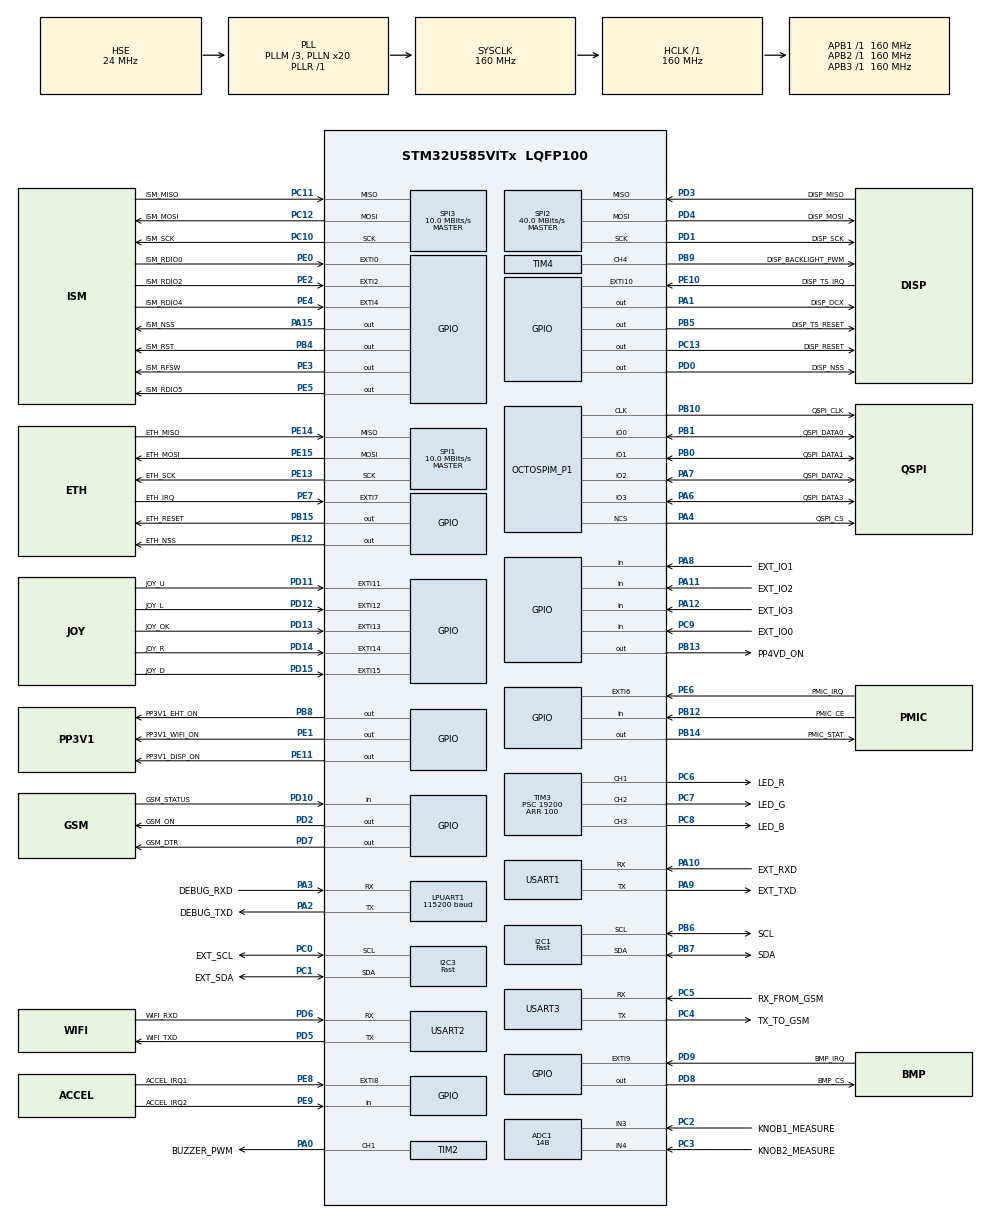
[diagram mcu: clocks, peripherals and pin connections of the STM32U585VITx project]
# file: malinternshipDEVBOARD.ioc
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ADC1.Channel-0\#ChannelRegularConversion=ADC_CHANNEL_3
ADC1.Channel-1\#ChannelRegularConversion=ADC_CHANNEL_4
ADC1.ClockPrescaler=ADC_CLOCK_ASYNC_DIV8
ADC1.ContinuousConvMode=ENABLE
ADC1.ConversionDataManagement=ADC_CONVERSIONDATA_DMA_CIRCULAR
ADC1.EOCSelection=ADC_EOC_SEQ_CONV
ADC1.EnableInjectedConversion=DISABLE
ADC1.EnableRegularConversion=ENABLE
ADC1.MonitoredBy-0\#ChannelRegularConversion=__NULL
ADC1.MonitoredBy-1\#ChannelRegularConversion=__NULL
ADC1.NbrOfConversion=2
ADC1.NbrOfConversionFlag=1
ADC1.OffsetNumber-0\#ChannelRegularConversion=ADC_OFFSET_NONE
ADC1.OffsetNumber-1\#ChannelRegularConversion=ADC_OFFSET_NONE
ADC1.OversamplingMode=ENABLE
ADC1.Rank-0\#ChannelRegularConversion=1
ADC1.Rank-1\#ChannelRegularConversion=2
ADC1.Ratio=15
ADC1.Resolution=ADC_RESOLUTION_14B
ADC1.SamplingTime-0\#ChannelRegularConversion=ADC_SAMPLETIME_68CYCLES
ADC1.SamplingTime-1\#ChannelRegularConversion=ADC_SAMPLETIME_68CYCLES
ADC1.TriggerFrequencyMode=ADC_TRIGGER_FREQ_HIGH
ADC1.master=1
CORTEX_M33_NS.userName=CORTEX_M33
GPDMA1.CIRCULARMODE_GPDMACH0=DISABLE
GPDMA1.CIRCULARMODE_GPDMACH5=ENABLE
GPDMA1.CIRCULARMODE_GPDMACH9=ENABLE
GPDMA1.DATAHANDLING_GPDMACH5=NONE
GPDMA1.DESTDATAWIDTH_GPDMACH5=DMA_DEST_DATAWIDTH_WORD
GPDMA1.DESTINC_GPDMACH0=DMA_DINC_FIXED
GPDMA1.DESTINC_GPDMACH2=DMA_DINC_INCREMENTED
GPDMA1.DESTINC_GPDMACH4=DMA_DINC_INCREMENTED
GPDMA1.DESTINC_GPDMACH5=DMA_DINC_INCREMENTED
GPDMA1.DESTINC_GPDMACH6=DMA_DINC_INCREMENTED
GPDMA1.DESTINC_GPDMACH9=DMA_DINC_INCREMENTED
GPDMA1.DIRECTION_GPDMACH0=DMA_MEMORY_TO_PERIPH
GPDMA1.DIRECTION_GPDMACH1=DMA_MEMORY_TO_PERIPH
GPDMA1.DIRECTION_GPDMACH3=DMA_MEMORY_TO_PERIPH
GPDMA1.DIRECTION_GPDMACH7=DMA_MEMORY_TO_PERIPH
GPDMA1.IPHANDLE_GPDMACH0-SIMPLEREQUEST_GPDMACH0=__NULL
GPDMA1.IPHANDLE_GPDMACH1-SIMPLEREQUEST_GPDMACH1=__NULL
GPDMA1.IPHANDLE_GPDMACH2-SIMPLEREQUEST_GPDMACH2=__NULL
GPDMA1.IPHANDLE_GPDMACH3-SIMPLEREQUEST_GPDMACH3=__NULL
GPDMA1.IPHANDLE_GPDMACH4-SIMPLEREQUEST_GPDMACH4=__NULL
GPDMA1.IPHANDLE_GPDMACH5-SIMPLEREQUEST_GPDMACH5=__NULL
GPDMA1.IPHANDLE_GPDMACH6-SIMPLEREQUEST_GPDMACH6=__NULL
GPDMA1.IPHANDLE_GPDMACH7-SIMPLEREQUEST_GPDMACH7=__NULL
GPDMA1.IPHANDLE_GPDMACH8-SIMPLEREQUEST_GPDMACH8=__NULL
GPDMA1.IPHANDLE_GPDMACH9-SIMPLEREQUEST_GPDMACH9=__NULL
GPDMA1.PRIORITY_GPDMACH0=DMA_LOW_PRIORITY_MID_WEIGHT
GPDMA1.PRIORITY_GPDMACH1=DMA_LOW_PRIORITY_MID_WEIGHT
GPDMA1.PRIORITY_GPDMACH2=DMA_LOW_PRIORITY_HIGH_WEIGHT
GPDMA1.PRIORITY_GPDMACH3=DMA_LOW_PRIORITY_MID_WEIGHT
GPDMA1.PRIORITY_GPDMACH4=DMA_LOW_PRIORITY_HIGH_WEIGHT
GPDMA1.PRIORITY_GPDMACH8=DMA_LOW_PRIORITY_HIGH_WEIGHT
GPDMA1.PRIORITY_LL_CIRCULAR_GPDMACH5=DMA_LOW_PRIORITY_MID_WEIGHT
GPDMA1.PRIORITY_LL_CIRCULAR_GPDMACH9=DMA_LOW_PRIORITY_HIGH_WEIGHT
GPDMA1.REQUEST_GPDMACH0=GPDMA1_REQUEST_LPUART1_TX
GPDMA1.REQUEST_GPDMACH1=GPDMA1_REQUEST_I2C1_TX
GPDMA1.REQUEST_GPDMACH2=GPDMA1_REQUEST_I2C1_RX
GPDMA1.REQUEST_GPDMACH3=GPDMA1_REQUEST_I2C3_TX
GPDMA1.REQUEST_GPDMACH4=GPDMA1_REQUEST_I2C3_RX
GPDMA1.REQUEST_GPDMACH5=GPDMA1_REQUEST_ADC1
GPDMA1.REQUEST_GPDMACH6=GPDMA1_REQUEST_SPI3_RX
GPDMA1.REQUEST_GPDMACH7=GPDMA1_REQUEST_SPI3_TX
GPDMA1.REQUEST_GPDMACH8=GPDMA1_REQUEST_SPI2_TX
GPDMA1.REQUEST_GPDMACH9=GPDMA1_REQUEST_USART1_RX
GPDMA1.SRCDATAWIDTH_GPDMACH5=DMA_SRC_DATAWIDTH_WORD
GPDMA1.SRCINC_GPDMACH0=DMA_SINC_INCREMENTED
GPDMA1.SRCINC_GPDMACH1=DMA_SINC_INCREMENTED
GPDMA1.SRCINC_GPDMACH3=DMA_SINC_INCREMENTED
GPDMA1.SRCINC_GPDMACH7=DMA_SINC_INCREMENTED
GPDMA1.SRCINC_GPDMACH8=DMA_SINC_INCREMENTED
I2C1.I2C_Speed_Mode=I2C_Fast
I2C1.Timing=0x00F07BFF
I2C3.I2C_Speed_Mode=I2C_Fast
I2C3.Timing=0x00F07BFF
IWDG.Prescaler=IWDG_PRESCALER_16
LPUART1.BaudRate=115200
Mcu.Family=STM32U5
Mcu.Name=STM32U585VITx
Mcu.Package=LQFP100
Mcu.UserConstants=I2C,hi2c1;EXT_I2C,hi2c3;LOG_UART,hlpuart1;FLASH_QSPI,hospi1;ETH_SPI,hspi1;DISP_SPI,hspi2;RFM_SPI,hspi3;EXT_UART,huart1;WIFI_UART,huart2;MODEM_UART,huart3;LED_R_TIM,htim3;LED_R_CH,TIM_CHANNEL_1;LED_G_TIM,htim3;LED_G_CH,TIM_CHANNEL_2;LED_B_TIM,htim3;LED_B_CH,TIM_CHANNEL_3
NVIC.ADC1_IRQn=true\:0\:0\:false\:false\:true\:false\:true\:true\:true
NVIC.EXTI0_IRQn=true\:0\:0\:false\:false\:true\:false\:true\:true\:true
NVIC.EXTI10_IRQn=true\:0\:0\:false\:false\:true\:false\:true\:true\:true
NVIC.EXTI11_IRQn=true\:0\:0\:false\:false\:true\:false\:true\:true\:true
NVIC.EXTI12_IRQn=true\:0\:0\:false\:false\:true\:false\:true\:true\:true
NVIC.EXTI13_IRQn=true\:0\:0\:false\:false\:true\:false\:true\:true\:true
NVIC.EXTI14_IRQn=true\:0\:0\:false\:false\:true\:false\:true\:true\:true
NVIC.EXTI15_IRQn=true\:0\:0\:false\:false\:true\:false\:true\:true\:true
NVIC.EXTI2_IRQn=true\:0\:0\:false\:false\:true\:false\:true\:true\:true
NVIC.EXTI4_IRQn=true\:0\:0\:false\:false\:true\:false\:true\:true\:true
NVIC.EXTI6_IRQn=true\:0\:0\:false\:false\:true\:false\:true\:true\:true
NVIC.EXTI7_IRQn=true\:0\:0\:false\:false\:true\:false\:true\:true\:true
NVIC.EXTI8_IRQn=true\:0\:0\:false\:false\:true\:false\:true\:true\:true
NVIC.EXTI9_IRQn=true\:0\:0\:false\:false\:true\:false\:true\:true\:true
NVIC.GPDMA1_Channel0_IRQn=true\:0\:0\:false\:false\:true\:true\:false\:true\:true
NVIC.GPDMA1_Channel1_IRQn=true\:0\:0\:false\:false\:true\:true\:false\:true\:true
NVIC.GPDMA1_Channel2_IRQn=true\:0\:0\:false\:false\:true\:true\:false\:true\:true
NVIC.GPDMA1_Channel3_IRQn=true\:0\:0\:false\:false\:true\:true\:false\:true\:true
NVIC.GPDMA1_Channel4_IRQn=true\:0\:0\:false\:false\:true\:true\:false\:true\:true
NVIC.GPDMA1_Channel5_IRQn=true\:0\:0\:false\:false\:true\:true\:false\:true\:true
NVIC.GPDMA1_Channel6_IRQn=true\:0\:0\:false\:false\:true\:true\:false\:true\:true
NVIC.GPDMA1_Channel7_IRQn=true\:0\:0\:false\:false\:true\:true\:false\:true\:true
NVIC.GPDMA1_Channel8_IRQn=true\:0\:0\:false\:false\:true\:true\:false\:true\:true
NVIC.GPDMA1_Channel9_IRQn=true\:0\:0\:false\:false\:true\:true\:false\:true\:true
NVIC.I2C1_ER_IRQn=true\:5\:0\:true\:false\:true\:false\:true\:true\:true
NVIC.I2C1_EV_IRQn=true\:5\:0\:true\:false\:true\:false\:true\:true\:true
NVIC.I2C3_ER_IRQn=true\:5\:0\:true\:false\:true\:false\:true\:true\:true
NVIC.I2C3_EV_IRQn=true\:5\:0\:true\:false\:true\:false\:true\:true\:true
NVIC.IWDG_IRQn=true\:0\:0\:false\:false\:true\:false\:true\:true\:true
NVIC.LPUART1_IRQn=true\:0\:0\:false\:false\:true\:false\:true\:true\:true
NVIC.OCTOSPI1_IRQn=true\:0\:0\:false\:false\:true\:false\:true\:true\:true
NVIC.PriorityGroup=NVIC_PRIORITYGROUP_4
NVIC.SPI2_IRQn=true\:0\:0\:false\:false\:true\:false\:true\:true\:true
NVIC.SPI3_IRQn=true\:0\:0\:false\:false\:true\:false\:false\:true\:true
NVIC.TIM17_IRQn=true\:15\:0\:false\:false\:true\:false\:false\:true\:true
NVIC.TIM2_IRQn=true\:4\:0\:true\:false\:true\:false\:true\:true\:true
NVIC.TIM7_IRQn=true\:0\:0\:false\:false\:true\:false\:true\:true\:true
NVIC.TimeBase=TIM17_IRQn
NVIC.TimeBaseIP=TIM17
NVIC.USART1_IRQn=true\:0\:0\:false\:false\:true\:false\:true\:true\:true
OCTOSPI1.ClockPrescaler=6
OCTOSPI1.DeviceSize=24
PA0.GPIO_Label=BUZZER_PWM
PA0.PinAttribute=Free
PA0.Signal=S_TIM2_CH1
PA1.GPIO_Label=DISP_DCX
PA1.PinAttribute=Free
PA1.Signal=GPIO_Output
PA10.GPIO_Label=EXT_RXD
PA10.GPIO_PuPd=GPIO_PULLUP
PA10.Mode=Asynchronous
PA10.PinAttribute=Free
PA10.Signal=USART1_RX
PA11.GPIO_Label=EXT_IO2
PA11.GPIO_PuPd=GPIO_PULLUP
PA11.PinAttribute=Free
PA11.Signal=GPIO_Input
PA12.GPIO_Label=EXT_IO3
PA12.GPIO_PuPd=GPIO_PULLUP
PA12.PinAttribute=Free
PA12.Signal=GPIO_Input
PA13\ (JTMS/SWDIO).Mode=Serial_Wire
PA13\ (JTMS/SWDIO).PinAttribute=Free
PA13\ (JTMS/SWDIO).Signal=DEBUG_JTMS-SWDIO
PA14\ (JTCK/SWCLK).Mode=Serial_Wire
PA14\ (JTCK/SWCLK).PinAttribute=Free
PA14\ (JTCK/SWCLK).Signal=DEBUG_JTCK-SWCLK
PA15\ (JTDI).GPIO_Label=ISM_NSS
PA15\ (JTDI).GPIO_Speed=GPIO_SPEED_FREQ_LOW
PA15\ (JTDI).PinState=GPIO_PIN_SET
PA15\ (JTDI).Signal=GPIO_Output
PA2.GPIO_Label=DEBUG_TXD
PA2.Mode=Asynchronous
PA2.PinAttribute=Free
PA2.Signal=LPUART1_TX
PA3.GPIO_Label=DEBUG_RXD
PA3.Mode=Asynchronous
PA3.PinAttribute=Free
PA3.Signal=LPUART1_RX
PA4.GPIO_Label=QSPI_CS
PA4.Mode=OCTOSPI1_Port1_NCS
PA4.Signal=OCTOSPIM_P1_NCS
PA6.GPIO_Label=QSPI_DATA3
PA6.Mode=OCTOSPI1_IOL_Port1L
PA6.Signal=OCTOSPIM_P1_IO3
PA7.GPIO_Label=QSPI_DATA2
PA7.Mode=OCTOSPI1_IOL_Port1L
PA7.Signal=OCTOSPIM_P1_IO2
PA8.GPIO_Label=EXT_IO1
PA8.GPIO_PuPd=GPIO_PULLUP
PA8.PinAttribute=Free
PA8.Signal=GPIO_Input
PA9.GPIO_Label=EXT_TXD
PA9.GPIO_PuPd=GPIO_PULLUP
PA9.Mode=Asynchronous
PA9.PinAttribute=Free
PA9.Signal=USART1_TX
PB0.GPIO_Label=QSPI_DATA1
PB0.Mode=OCTOSPI1_IOL_Port1L
PB0.Signal=OCTOSPIM_P1_IO1
PB1.GPIO_Label=QSPI_DATA0
PB1.Mode=OCTOSPI1_IOL_Port1L
PB1.Signal=OCTOSPIM_P1_IO0
PB10.GPIO_Label=QSPI_CLK
PB10.Mode=O1_P1_CLK
PB10.Signal=OCTOSPIM_P1_CLK
PB12.GPIO_Label=PMIC_CE
PB12.Signal=GPIO_Input
PB13.GPIO_Label=PP4VD_ON
PB13.Signal=GPIO_Output
PB14.GPIO_Label=PMIC_STAT
PB14.Signal=GPIO_Output
PB15.GPIO_Label=ETH_RESET
PB15.Signal=GPIO_Output
PB2.GPIO_Label=EXT_SMBA
PB2.Signal=I2C3_SMBA
PB4\ (NJTRST).GPIO_Label=ISM_RST
PB4\ (NJTRST).Signal=GPIO_Output
PB5.GPIO_Label=DISP_TS_RESET
PB5.Signal=GPIO_Output
PB6.GPIO_Label=SCL
PB6.GPIO_Speed=GPIO_SPEED_FREQ_HIGH
PB6.Mode=I2C
PB6.Signal=I2C1_SCL
PB7.GPIO_Label=SDA
PB7.GPIO_Speed=GPIO_SPEED_FREQ_HIGH
PB7.Mode=I2C
PB7.Signal=I2C1_SDA
PB8.GPIO_Label=PP3V1_EHT_ON
PB8.Signal=GPIO_Output
PB9.GPIO_Label=DISP_BACKLIGHT_PWM
PB9.Signal=S_TIM4_CH4
PC0.GPIO_Label=EXT_SCL
PC0.GPIO_Speed=GPIO_SPEED_FREQ_HIGH
PC0.Mode=I2C
PC0.PinAttribute=Free
PC0.Signal=I2C3_SCL
PC1.GPIO_Label=EXT_SDA
PC1.GPIO_Speed=GPIO_SPEED_FREQ_HIGH
PC1.Mode=I2C
PC1.PinAttribute=Free
PC1.Signal=I2C3_SDA
PC10.GPIO_Label=ISM_SCK
PC10.Mode=Full_Duplex_Master
PC10.Signal=SPI3_SCK
PC11.GPIO_Label=ISM_MISO
PC11.Mode=Full_Duplex_Master
PC11.Signal=SPI3_MISO
PC12.GPIO_Label=ISM_MOSI
PC12.Mode=Full_Duplex_Master
PC12.PinAttribute=Free
PC12.Signal=SPI3_MOSI
PC13.GPIO_Label=DISP_RESET
PC13.Signal=GPIO_Output
PC14-OSC32_IN\ (PC14).Mode=LSE-External-Oscillator
PC14-OSC32_IN\ (PC14).Signal=RCC_OSC32_IN
PC15-OSC32_OUT\ (PC15).Mode=LSE-External-Oscillator
PC15-OSC32_OUT\ (PC15).Signal=RCC_OSC32_OUT
PC2.GPIO_Label=KNOB1_MEASURE
PC2.Mode=IN3-Single-Ended
PC2.PinAttribute=Free
PC2.Signal=ADC1_IN3
PC3.GPIO_Label=KNOB2_MEASURE
PC3.Mode=IN4-Single-Ended
PC3.PinAttribute=Free
PC3.Signal=ADC1_IN4
PC4.GPIO_Label=TX_TO_GSM
PC4.Mode=Asynchronous
PC4.Signal=USART3_TX
PC5.GPIO_Label=RX_FROM_GSM
PC5.Mode=Asynchronous
PC5.Signal=USART3_RX
PC6.GPIO_Label=LED_R
PC6.Signal=S_TIM3_CH1
PC7.GPIO_Label=LED_G
PC7.Signal=S_TIM3_CH2
PC8.GPIO_Label=LED_B
PC8.PinAttribute=Free
PC8.Signal=S_TIM3_CH3
PC9.GPIO_Label=EXT_IO0
PC9.GPIO_PuPd=GPIO_PULLUP
PC9.PinAttribute=Free
PC9.Signal=GPIO_Input
PD0.GPIO_Label=DISP_NSS
PD0.GPIO_Speed=GPIO_SPEED_FREQ_LOW
PD0.PinAttribute=Free
PD0.PinState=GPIO_PIN_SET
PD0.Signal=GPIO_Output
PD1.GPIO_Label=DISP_SCK
PD1.GPIO_Speed=GPIO_SPEED_FREQ_VERY_HIGH
PD1.Mode=Full_Duplex_Master
PD1.PinAttribute=Free
PD1.Signal=SPI2_SCK
PD10.GPIO_Label=GSM_STATUS
PD10.Signal=GPIO_Input
PD11.GPIO_Label=JOY_U
PD11.GPIO_ModeDefaultEXTI=GPIO_MODE_IT_RISING_FALLING
PD11.Signal=GPXTI11
PD12.GPIO_Label=JOY_L
PD12.GPIO_ModeDefaultEXTI=GPIO_MODE_IT_RISING_FALLING
PD12.PinAttribute=Free
PD12.Signal=GPXTI12
PD13.GPIO_Label=JOY_OK
PD13.GPIO_ModeDefaultEXTI=GPIO_MODE_IT_RISING_FALLING
PD13.PinAttribute=Free
PD13.Signal=GPXTI13
PD14.GPIO_Label=JOY_R
PD14.GPIO_ModeDefaultEXTI=GPIO_MODE_IT_RISING_FALLING
PD14.Signal=GPXTI14
PD15.GPIO_Label=JOY_D
PD15.GPIO_ModeDefaultEXTI=GPIO_MODE_IT_RISING_FALLING
PD15.GPIO_PuPd=GPIO_NOPULL
PD15.Signal=GPXTI15
PD2.GPIO_Label=GSM_ON
PD2.PinAttribute=Free
PD2.Signal=GPIO_Output
PD3.GPIO_Label=DISP_MISO
PD3.GPIO_Speed=GPIO_SPEED_FREQ_VERY_HIGH
PD3.Mode=Full_Duplex_Master
PD3.Signal=SPI2_MISO
PD4.GPIO_Label=DISP_MOSI
PD4.GPIO_Speed=GPIO_SPEED_FREQ_VERY_HIGH
PD4.Mode=Full_Duplex_Master
PD4.Signal=SPI2_MOSI
PD5.GPIO_Label=WIFI_TXD
PD5.Mode=Asynchronous
PD5.Signal=USART2_TX
PD6.GPIO_Label=WIFI_RXD
PD6.Mode=Asynchronous
PD6.Signal=USART2_RX
PD7.GPIO_Label=GSM_DTR
PD7.Signal=GPIO_Output
PD8.GPIO_Label=BMP_CS
PD8.GPIO_Speed=GPIO_SPEED_FREQ_LOW
PD8.PinState=GPIO_PIN_SET
PD8.Signal=GPIO_Output
PD9.GPIO_Label=BMP_IRQ
PD9.Signal=GPXTI9
PE0.GPIO_Label=ISM_RDIO0
PE0.GPIO_ModeDefaultEXTI=GPIO_MODE_IT_FALLING
PE0.Signal=GPXTI0
PE1.GPIO_Label=PP3V1_WIFI_ON
PE1.Signal=GPIO_Output
PE10.GPIO_Label=DISP_TS_IRQ
PE10.Signal=GPXTI10
PE11.GPIO_Label=PP3V1_DISP_ON
PE11.Signal=GPIO_Output
PE12.GPIO_Label=ETH_NSS
PE12.GPIO_Speed=GPIO_SPEED_FREQ_LOW
PE12.PinState=GPIO_PIN_SET
PE12.Signal=GPIO_Output
PE13.GPIO_Label=ETH_SCK
PE13.Mode=Full_Duplex_Master
PE13.Signal=SPI1_SCK
PE14.GPIO_Label=ETH_MISO
PE14.Mode=Full_Duplex_Master
PE14.Signal=SPI1_MISO
PE15.GPIO_Label=ETH_MOSI
PE15.Mode=Full_Duplex_Master
PE15.Signal=SPI1_MOSI
PE2.GPIO_Label=ISM_RDIO2
PE2.GPIO_ModeDefaultEXTI=GPIO_MODE_IT_RISING
PE2.Signal=GPXTI2
PE3.GPIO_Label=ISM_RFSW
PE3.Signal=GPIO_Output
PE4.GPIO_Label=ISM_RDIO4
PE4.GPIO_ModeDefaultEXTI=GPIO_MODE_IT_RISING_FALLING
PE4.Signal=GPXTI4
PE5.GPIO_Label=ISM_RDIO5
PE5.Signal=GPIO_Output
PE6.GPIO_Label=PMIC_IRQ
PE6.Signal=GPXTI6
PE7.GPIO_Label=ETH_IRQ
PE7.Signal=GPXTI7
PE8.GPIO_Label=ACCEL_IRQ1
PE8.Signal=GPXTI8
PE9.GPIO_Label=ACCEL_IRQ2
PE9.Signal=GPIO_Input
PH0-OSC_IN\ (PH0).Mode=HSE-External-Oscillator
PH0-OSC_IN\ (PH0).Signal=RCC_OSC_IN
PH1-OSC_OUT\ (PH1).Mode=HSE-External-Oscillator
PH1-OSC_OUT\ (PH1).Signal=RCC_OSC_OUT
ProjectManager.HeapSize=0x200
ProjectManager.StackSize=0x400
ProjectManager.TargetToolchain=Makefile
RCC.ADCFreq_Value=16000000
RCC.AHBFreq_Value=160000000
RCC.APB1Freq_Value=160000000
RCC.APB1TimFreq_Value=160000000
RCC.APB2Freq_Value=160000000
RCC.APB2TimFreq_Value=160000000
RCC.APB3Freq_Value=160000000
RCC.CortexFreq_Value=160000000
RCC.DACCLockSelectionVirtual=RCC_DAC1CLKSOURCE_LSI
RCC.DACCLockSelectionVirtualString=RCC_DAC1CLKSOURCE_LSI
RCC.EPOD_VALUE=24000000
RCC.HCLKFreq_Value=160000000
RCC.HSE_VALUE=24000000
RCC.HSI48_VALUE=48000000
RCC.HSI_VALUE=16000000
RCC.LSIDIV_VALUE=32000
RCC.MSIClockRange=RCC_MSIRANGE_0
RCC.MSI_VALUE=48000000
RCC.PLL1R=1
RCC.PLL2FRACN=0
RCC.PLL3FRACN=0
RCC.PLLFRACN=0
RCC.PLLM=3
RCC.PLLN=20
RCC.PLLSourceVirtual=RCC_PLLSOURCE_HSE
RCC.SYSCLKFreq_VALUE=160000000
RCC.SYSCLKSource=RCC_SYSCLKSOURCE_PLLCLK
RCC.USBFreq_Value=48000000
RCC.VCOOutputFreq_Value=160000000
SH.S_TIM2_CH1.0=TIM2_CH1,PWM Generation1 CH1
SH.S_TIM3_CH1.0=TIM3_CH1,PWM Generation1 CH1
SH.S_TIM3_CH2.0=TIM3_CH2,PWM Generation2 CH2
SH.S_TIM3_CH3.0=TIM3_CH3,PWM Generation3 CH3
SH.S_TIM4_CH4.0=TIM4_CH4,PWM Generation4 CH4
SPI1.BaudRatePrescaler=SPI_BAUDRATEPRESCALER_16
SPI1.CalculateBaudRate=10.0 MBits/s
SPI1.DataSize=SPI_DATASIZE_8BIT
SPI1.Direction=SPI_DIRECTION_2LINES
SPI1.Mode=SPI_MODE_MASTER
SPI1.VirtualType=VM_MASTER
SPI2.BaudRatePrescaler=SPI_BAUDRATEPRESCALER_4
SPI2.CalculateBaudRate=40.0 MBits/s
SPI2.DataSize=SPI_DATASIZE_8BIT
SPI2.Direction=SPI_DIRECTION_2LINES
SPI2.Mode=SPI_MODE_MASTER
SPI2.VirtualType=VM_MASTER
SPI3.BaudRatePrescaler=SPI_BAUDRATEPRESCALER_16
SPI3.CalculateBaudRate=10.0 MBits/s
SPI3.Direction=SPI_DIRECTION_2LINES
SPI3.Mode=SPI_MODE_MASTER
SPI3.VirtualType=VM_MASTER
THREADX.TX_APP_MEM_POOL_SIZE=(64*1024)
THREADX.TX_MINIMUM_STACK=512
THREADX.TX_TIMER_THREAD_PRIORITY=2
THREADX.TX_TIMER_TICKS_PER_SECOND=1000
TIM2.Channel-PWM\ Generation1\ CH1=TIM_CHANNEL_1
TIM2.PeriodNoDither=256-1
TIM2.Prescaler=5-1
TIM3.AutoReloadPreload=TIM_AUTORELOAD_PRELOAD_ENABLE
TIM3.Channel-PWM\ Generation1\ CH1=TIM_CHANNEL_1
TIM3.Channel-PWM\ Generation2\ CH2=TIM_CHANNEL_2
TIM3.Channel-PWM\ Generation3\ CH3=TIM_CHANNEL_3
TIM3.PeriodNoDither=100
TIM3.Prescaler=19200
TIM4.AutoReloadPreload=TIM_AUTORELOAD_PRELOAD_ENABLE
TIM4.Channel-PWM\ Generation4\ CH4=TIM_CHANNEL_4
TIM4.PeriodNoDither=100
TIM4.Prescaler=5000
TIM7.PeriodNoDither=64000-1
TIM7.Prescaler=100-1
USART1.VirtualMode-Asynchronous=VM_ASYNC
USART2.VirtualMode-Asynchronous=VM_ASYNC
USART3.VirtualMode-Asynchronous=VM_ASYNC
VP_GPDMA1_VS_GPDMACH0.Mode=SIMPLEREQUEST_GPDMACH0
VP_GPDMA1_VS_GPDMACH1.Mode=SIMPLEREQUEST_GPDMACH1
VP_GPDMA1_VS_GPDMACH2.Mode=SIMPLEREQUEST_GPDMACH2
VP_GPDMA1_VS_GPDMACH3.Mode=SIMPLEREQUEST_GPDMACH3
VP_GPDMA1_VS_GPDMACH4.Mode=SIMPLEREQUEST_GPDMACH4
VP_GPDMA1_VS_GPDMACH5.Mode=SIMPLEREQUEST_GPDMACH5
VP_GPDMA1_VS_GPDMACH6.Mode=SIMPLEREQUEST_GPDMACH6
VP_GPDMA1_VS_GPDMACH7.Mode=SIMPLEREQUEST_GPDMACH7
VP_GPDMA1_VS_GPDMACH8.Mode=SIMPLEREQUEST_GPDMACH8
VP_GPDMA1_VS_GPDMACH9.Mode=SIMPLEREQUEST_GPDMACH9
VP_ICACHE_VS_ICACHE.Mode=DirectMappedCache
VP_IWDG_VS_IWDG.Mode=IWDG_Activate
VP_LPBAMQUEUE_VS_QUEUE.Mode=QUEUEMODE
VP_LPBAM_VS_SIG1.Mode=SmartRun
VP_LPBAM_VS_SIG4.Mode=LPDMA1
VP_OCTOSPI1_VS_quad.Mode=quad_mode
VP_PWR_VS_DBSignals.Mode=DisableDeadBatterySignals
VP_PWR_VS_LPOM.Mode=PowerOptimisation
VP_PWR_VS_SECSignals.Mode=Security/Privilege
VP_SYS_VS_tim17.Mode=TIM17
VP_THREADX_VS_RTOSJjThreadXJjCoreJjDefault.Mode=Core_Default
VP_TIM2_VS_ClockSourceINT.Mode=Internal
VP_TIM3_VS_ClockSourceINT.Mode=Internal
VP_TIM4_VS_ClockSourceINT.Mode=Internal
VP_TIM7_VS_ClockSourceINT.Mode=Enable_Timer
board=custom

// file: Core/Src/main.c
/* USER CODE BEGIN Header */
/**
 ******************************************************************************
 * @file           : main.c
 * @brief          : Main program body
 ******************************************************************************
 * @attention
 *
 * Copyright (c) 2022 STMicroelectronics.
 * All rights reserved.
 *
 * This software is licensed under terms that can be found in the LICENSE file
 * in the root directory of this software component.
 * If no LICENSE file comes with this software, it is provided AS-IS.
 *
 ******************************************************************************
 */
/* USER CODE END Header */
#include "main.h"
#include "app_threadx.h"
#include "adc.h"
#include "gpdma.h"
#include "i2c.h"
#include "icache.h"
#include "iwdg.h"
#include "usart.h"
#include "octospi.h"
#include "spi.h"
#include "tim.h"
#include "gpio.h"

/* USER CODE BEGIN Includes */
#include "loglib.h"
#include "esp32.h"
#include "parser.h"
#include "buzzer.h"
#include "boot_reason.h"
#include "display.h"
#include "flash.h"
#include "rfm66a.h"
#include "geode.h"

/* USER CODE END Includes */

void        SystemClock_Config(void);
static void SystemPower_Config(void);

int main(void) {

    /* MCU Configuration--------------------------------------------------------*/

    /* Reset of all peripherals, Initializes the Flash interface and the Systick. */
    HAL_Init();

    /* Configure the system clock */
    SystemClock_Config();

    /* Configure the System Power */
    SystemPower_Config();

    /* USER CODE BEGIN SysInit */
    GENERAL_GetResetStatus();

    HAL_PWREx_EnableVddA();
    /* USER CODE END SysInit */

    /* Initialize all configured peripherals */
    MX_GPIO_Init();
    MX_GPDMA1_Init();
    MX_SPI2_Init();
    MX_TIM4_Init();
    MX_I2C1_Init();
    MX_I2C3_Init();
    MX_USART1_UART_Init();
    MX_SPI3_Init();
    MX_SPI1_Init();
    MX_USART2_UART_Init();
    MX_ADC1_Init();
    MX_LPUART1_UART_Init();
    MX_USART3_UART_Init();
    MX_TIM3_Init();
    MX_OCTOSPI1_Init();
    MX_TIM2_Init();
    MX_ICACHE_Init();
    MX_IWDG_Init();
    MX_TIM7_Init();

    MX_ThreadX_Init();

    /* We should never get here as control is now taken by the scheduler */
    /* Infinite loop */
    while (1) {

    }
}

void SystemClock_Config(void) {
    RCC_OscInitTypeDef RCC_OscInitStruct = { 0 };
    RCC_ClkInitTypeDef RCC_ClkInitStruct = { 0 };

    /** Configure the main internal regulator output voltage
     */
    if (HAL_PWREx_ControlVoltageScaling(PWR_REGULATOR_VOLTAGE_SCALE1) != HAL_OK) {
        Error_Handler();
    }

    /** Initializes the CPU, AHB and APB buses clocks
     */
    RCC_OscInitStruct.OscillatorType = RCC_OSCILLATORTYPE_HSI | RCC_OSCILLATORTYPE_LSI | RCC_OSCILLATORTYPE_HSE;
    RCC_OscInitStruct.HSEState = RCC_HSE_ON;
    RCC_OscInitStruct.HSIState = RCC_HSI_ON;
    RCC_OscInitStruct.HSICalibrationValue = RCC_HSICALIBRATION_DEFAULT;
    RCC_OscInitStruct.LSIState = RCC_LSI_ON;
    RCC_OscInitStruct.LSIDiv = RCC_LSI_DIV1;
    RCC_OscInitStruct.PLL.PLLState = RCC_PLL_ON;
    RCC_OscInitStruct.PLL.PLLSource = RCC_PLLSOURCE_HSE;
    RCC_OscInitStruct.PLL.PLLMBOOST = RCC_PLLMBOOST_DIV2;
    RCC_OscInitStruct.PLL.PLLM = 3;
    RCC_OscInitStruct.PLL.PLLN = 20;
    RCC_OscInitStruct.PLL.PLLP = 2;
    RCC_OscInitStruct.PLL.PLLQ = 2;
    RCC_OscInitStruct.PLL.PLLR = 1;
    RCC_OscInitStruct.PLL.PLLRGE = RCC_PLLVCIRANGE_1;
    RCC_OscInitStruct.PLL.PLLFRACN = 0;
    if (HAL_RCC_OscConfig(&RCC_OscInitStruct) != HAL_OK) {
        Error_Handler();
    }

    /** Initializes the CPU, AHB and APB buses clocks
     */
    RCC_ClkInitStruct.ClockType =
        RCC_CLOCKTYPE_HCLK | RCC_CLOCKTYPE_SYSCLK | RCC_CLOCKTYPE_PCLK1 | RCC_CLOCKTYPE_PCLK2 | RCC_CLOCKTYPE_PCLK3;
    RCC_ClkInitStruct.SYSCLKSource = RCC_SYSCLKSOURCE_PLLCLK;
    RCC_ClkInitStruct.AHBCLKDivider = RCC_SYSCLK_DIV1;
    RCC_ClkInitStruct.APB1CLKDivider = RCC_HCLK_DIV1;
    RCC_ClkInitStruct.APB2CLKDivider = RCC_HCLK_DIV1;
    RCC_ClkInitStruct.APB3CLKDivider = RCC_HCLK_DIV1;

    if (HAL_RCC_ClockConfig(&RCC_ClkInitStruct, FLASH_LATENCY_4) != HAL_OK) {
        Error_Handler();
    }
}

/**
 * @brief Power Configuration
 * @retval None
 */
static void SystemPower_Config(void) {

    /*
     * Disable the internal Pull-Up in Dead Battery pins of UCPD peripheral
     */
    HAL_PWREx_DisableUCPDDeadBattery();
}

/* USER CODE BEGIN 4 */

void HAL_SPI_TxCpltCallback(SPI_HandleTypeDef *hspi) {
    if (hspi == &DISP_SPI) {
        ILI9341_TxCpltCallback();
    }
    if (hspi == &RFM_SPI) {
        RFM_SPI_SemRelease();
    }
}

void HAL_SPI_RxCpltCallback(SPI_HandleTypeDef *hspi) {
    if (hspi == &DISP_SPI) {
        ILI9341_RxCpltCallback();
    }
    if (hspi == &RFM_SPI) {
        RFM_SPI_SemRelease();
    }
}

void HAL_UART_TxCpltCallback(UART_HandleTypeDef *huart) {
    // if (huart == &MODEM_UART) {
    //     MOD_TxCpltCallback();
    // }
    if (huart == &LOG_UART) {
        LOG_TxCpltCallback();
    }
    if (huart == &EXT_UART) {
        ESP32_TxCallback();
    }
}

void HAL_UART_RxCpltCallback(UART_HandleTypeDef *huart) {
    if (huart == &LOG_UART) {
        PARSER_RxCpltCallback();
    }
    if (huart == &EXT_UART) {
        ESP32_RxCallback();
    }
}

void HAL_TIM_PWM_PulseFinishedCallback(TIM_HandleTypeDef *htim) {
    if (htim->Instance == TIM2) {
        BUZZER_TIM_PWM_PulseFinishedCallback(htim);
    }
}

void HAL_GPIO_EXTI_Rising_Callback(uint16_t GPIO_Pin) {
    if (GPIO_Pin == JOY_U_Pin) {
        LOG_DEBUG("UP BUTTON UNPRESSED");
    }
    if (GPIO_Pin == JOY_D_Pin) {
        LOG_DEBUG("DOWN BUTTON UNPRESSED");
    }
    if (GPIO_Pin == JOY_L_Pin) {
        LOG_DEBUG("LEFT BUTTON UNPRESSED");
    }
    if (GPIO_Pin == JOY_R_Pin) {
        LOG_DEBUG("RIGHT BUTTON UNPRESSED");
    }
    if (GPIO_Pin == JOY_OK_Pin) {
        LOG_DEBUG("OK BUTTON UNPRESSED");
    }
    if (GPIO_Pin == ISM_RDIO2_Pin) {
        RFM_SemRelease();
    }
}

void HAL_GPIO_EXTI_Falling_Callback(uint16_t GPIO_Pin) {
    if (GPIO_Pin == JOY_U_Pin) {
        LOG_DEBUG("UP BUTTON PRESSED");
    }
    if (GPIO_Pin == JOY_D_Pin) {
        LOG_DEBUG("DOWN BUTTON PRESSED");
    }
    if (GPIO_Pin == JOY_L_Pin) {
        LOG_DEBUG("LEFT BUTTON PRESSED");
    }
    if (GPIO_Pin == JOY_R_Pin) {
        LOG_DEBUG("RIGHT BUTTON PRESSED");
    }
    if (GPIO_Pin == JOY_OK_Pin) {
        LOG_DEBUG("OK BUTTON PRESSED");
    }
    if (GPIO_Pin == ISM_RDIO0_Pin || GPIO_Pin == ISM_RDIO4_Pin) {
        RFM_SemRelease();
    }
}

void HAL_OSPI_StatusMatchCallback(OSPI_HandleTypeDef *hospi) {
    if (hospi == &FLASH_QSPI) {
        IS25L_StatusMatchCallback();
    }
}

void HAL_OSPI_RxCpltCallback(OSPI_HandleTypeDef *hospi) {
    if (hospi == &FLASH_QSPI) {
        IS25L_RxCompleteCallback();
    }
}

void HAL_OSPI_TxCpltCallback(OSPI_HandleTypeDef *hospi) {
    if (hospi == &FLASH_QSPI) {
        IS25L_TxCompleteCallback();
    }
}

void HAL_OSPI_CmdCpltCallback(OSPI_HandleTypeDef *hospi) {
    if (hospi == &FLASH_QSPI) {
        IS25L_CmdCompleteCallback();
    }
}

/* USER CODE END 4 */

void HAL_TIM_PeriodElapsedCallback(TIM_HandleTypeDef *htim) {
    /* USER CODE BEGIN Callback 0 */
    GOD_TIM_Callback(htim);
    /* USER CODE END Callback 0 */
    if (htim->Instance == TIM17) {
        HAL_IncTick();
    }
    /* USER CODE BEGIN Callback 1 */
    if (htim->Instance == TIM17) {
        lv_tick_inc(1);
    }

    /* USER CODE END Callback 1 */
}

void Error_Handler(void) {
    __disable_irq();
    while (1) {
    }
}
